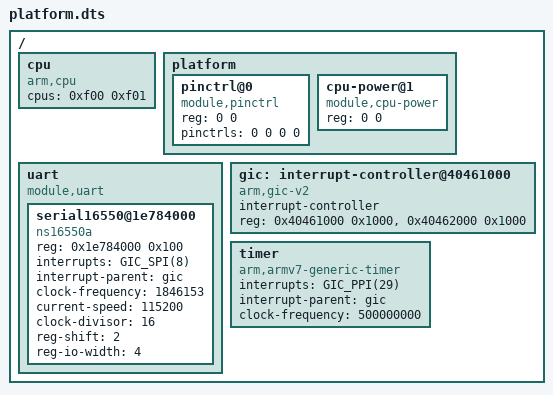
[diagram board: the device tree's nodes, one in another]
/*
 * SPDX-License-Identifier: Apache-2.0
 * Copyright (c) 2025 KapaXL (kapa.xl@outlook.com)
 */

/dts-v1/;

#include "memory.dtsi"
#include <generated/autoconf.h>

#define GIC_SPI(x) ((x) + 32)
#define GIC_PPI(x) ((x))

/ {
	cpu {
		compatible = "arm,cpu";
		/* mpid of each CPU */
		cpus = <0xf00 0xf01>;
	};

	platform {
		#address-cells = <1>;
		#size-cells = <1>;

		/*
		 * pinctrls cells information
		 * 0: reg offset,
		 * 1: first bit position,
		 * 2: number of bits,
		 * 3: value
		 */
		pinctrl@0 {
			/* unnecessary for QEMU */
			compatible = "module,pinctrl";
			reg = <0 0>;
			pinctrls = <0 0 0 0>;
		};

		cpu-power@1 {
			compatible = "module,cpu-power";
			/* unnecessary for QEMU */
			reg = <0 0>;
		};
	};

	uart {
		compatible = "module,uart";
		#address-cells = <1>;
		#size-cells = <1>;

		serial16550@1e784000 {
			compatible = "ns16550a";
			reg = <0x1e784000 0x100>;
#if !defined(CONFIG_REE)
			interrupts = <GIC_SPI(8)>;
#endif
			interrupt-parent = <&gic>;
			clock-frequency = <1846153>;
			current-speed = <115200>;
			clock-divisor = <16>;
			reg-shift = <2>;
			reg-io-width = <4>;
		};
	};

	/* interrupt-controller: CPU side */
	gic: interrupt-controller@40461000 {
		compatible = "arm,gic-v2";

		interrupt-controller;

		#interrupt-cells = <1>;
		#address-cells = <1>;

		reg = <0x40461000 0x1000>, /* GICD */
			<0x40462000 0x1000>; /* GICC */
	};

	timer {
		compatible = "arm,armv7-generic-timer";
		interrupts = <GIC_PPI(29)>; /* PPI 29 for SecureWorld tick_timer, 30 for REE */
		interrupt-parent = <&gic>;
		clock-frequency = <500000000>;
	};
};
